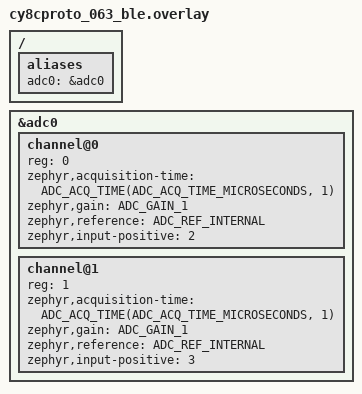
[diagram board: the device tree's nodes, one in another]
/*
 * Copyright (c) 2024 Centro de Inovacao EDGE
 *
 * SPDX-License-Identifier: Apache-2.0
 */

#include <zephyr/dt-bindings/adc/adc.h>

/ {
	aliases {
		adc0 = &adc0;
	};
};

&adc0 {
	status = "okay";
	#address-cells = <1>;
	#size-cells = <0>;

	channel@0 {
		reg = <0>;
		zephyr,acquisition-time = <ADC_ACQ_TIME(ADC_ACQ_TIME_MICROSECONDS, 1)>;
		zephyr,gain = "ADC_GAIN_1";
		zephyr,reference = "ADC_REF_INTERNAL";
		zephyr,input-positive = <2>;   /* P10.2 */
	};

	channel@1 {
		reg = <1>;
		zephyr,acquisition-time = <ADC_ACQ_TIME(ADC_ACQ_TIME_MICROSECONDS, 1)>;
		zephyr,gain = "ADC_GAIN_1";
		zephyr,reference = "ADC_REF_INTERNAL";
		zephyr,input-positive = <3>;   /* P10.3 */
	};
};
